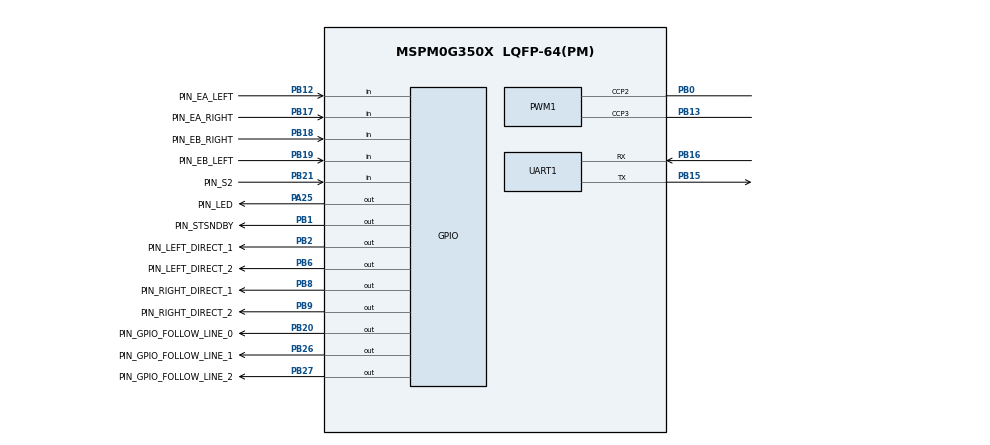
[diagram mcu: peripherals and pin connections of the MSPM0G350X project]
/**
 * @cliArgs --device "MSPM0G350X" --part "Default" --package "LQFP-64(PM)" --product "mspm0_sdk@2.04.00.06"
 * @versions {"tool":"1.24.0+4110"}
 */

/**
 * Import the modules used in this configuration.
 */
const ADC12  = scripting.addModule("/ti/driverlib/ADC12", {}, false);
const ADC121 = ADC12.addInstance();
const GPIO   = scripting.addModule("/ti/driverlib/GPIO", {}, false);
const GPIO1  = GPIO.addInstance();
const GPIO2  = GPIO.addInstance();
const GPIO3  = GPIO.addInstance();
const GPIO4  = GPIO.addInstance();
const GPIO5  = GPIO.addInstance();
const GPIO6  = GPIO.addInstance();
const PWM    = scripting.addModule("/ti/driverlib/PWM", {}, false);
const PWM1   = PWM.addInstance();
const SYSCTL = scripting.addModule("/ti/driverlib/SYSCTL");
const TIMER  = scripting.addModule("/ti/driverlib/TIMER", {}, false);
const TIMER1 = TIMER.addInstance();
const TIMER2 = TIMER.addInstance();
const UART   = scripting.addModule("/ti/driverlib/UART", {}, false);
const UART1  = UART.addInstance();

/**
 * Write custom configuration values to the imported modules.
 */
const divider6       = system.clockTree["PLL_CLK2X_DIV"];
divider6.divideValue = 4;

const divider7       = system.clockTree["PLL_PDIV"];
divider7.divideValue = 2;

const divider9       = system.clockTree["UDIV"];
divider9.divideValue = 2;

const multiplier2         = system.clockTree["PLL_QDIV"];
multiplier2.multiplyValue = 10;

const mux8       = system.clockTree["HSCLKMUX"];
mux8.inputSelect = "HSCLKMUX_SYSPLL2X";

ADC121.$name                             = "ADC12_FOLLOW_LINE";
ADC121.enableDMA                         = false;
ADC121.sampClkDiv                        = "DL_ADC12_CLOCK_DIVIDE_8";
ADC121.adcMem0_name                      = "ADC_Channel0";
ADC121.powerDownMode                     = "DL_ADC12_POWER_DOWN_MODE_MANUAL";
ADC121.sampleTime0                       = "0";
ADC121.peripheral.$assign                = "ADC0";
ADC121.peripheral.adcPin0.$assign        = "PA27";
ADC121.adcPin0Config.hideOutputInversion = scripting.forceWrite(false);
ADC121.adcPin0Config.$name               = "ti_driverlib_gpio_GPIOPinGeneric12";

const Board = scripting.addModule("/ti/driverlib/Board", {}, false);

GPIO1.$name                              = "GPIO_MOTOR";
GPIO1.port                               = "PORTB";
GPIO1.associatedPins.create(5);
GPIO1.associatedPins[0].$name            = "PIN_STSNDBY";
GPIO1.associatedPins[0].pin.$assign      = "PB1";
GPIO1.associatedPins[1].$name            = "PIN_LEFT_DIRECT_1";
GPIO1.associatedPins[1].internalResistor = "PULL_DOWN";
GPIO1.associatedPins[1].pin.$assign      = "PB2";
GPIO1.associatedPins[2].$name            = "PIN_LEFT_DIRECT_2";
GPIO1.associatedPins[2].internalResistor = "PULL_DOWN";
GPIO1.associatedPins[2].pin.$assign      = "PB6";
GPIO1.associatedPins[3].$name            = "PIN_RIGHT_DIRECT_1";
GPIO1.associatedPins[3].internalResistor = "PULL_DOWN";
GPIO1.associatedPins[3].pin.$assign      = "PB8";
GPIO1.associatedPins[4].$name            = "PIN_RIGHT_DIRECT_2";
GPIO1.associatedPins[4].internalResistor = "PULL_DOWN";
GPIO1.associatedPins[4].pin.$assign      = "PB9";

GPIO2.$name                              = "GPIO_ENCODER_LEFT";
GPIO2.associatedPins.create(2);
GPIO2.associatedPins[0].$name            = "PIN_EA_LEFT";
GPIO2.associatedPins[0].direction        = "INPUT";
GPIO2.associatedPins[0].assignedPort     = "PORTB";
GPIO2.associatedPins[0].interruptEn      = true;
GPIO2.associatedPins[0].polarity         = "FALL";
GPIO2.associatedPins[0].internalResistor = "PULL_UP";
GPIO2.associatedPins[0].pin.$assign      = "PB12";
GPIO2.associatedPins[1].$name            = "PIN_EB_LEFT";
GPIO2.associatedPins[1].direction        = "INPUT";
GPIO2.associatedPins[1].internalResistor = "PULL_UP";
GPIO2.associatedPins[1].assignedPort     = "PORTB";
GPIO2.associatedPins[1].pin.$assign      = "PB19";

GPIO3.$name                              = "GPIO_ENCODER_RIGHT";
GPIO3.associatedPins.create(2);
GPIO3.associatedPins[0].$name            = "PIN_EA_RIGHT";
GPIO3.associatedPins[0].direction        = "INPUT";
GPIO3.associatedPins[0].internalResistor = "PULL_UP";
GPIO3.associatedPins[0].interruptEn      = true;
GPIO3.associatedPins[0].polarity         = "FALL";
GPIO3.associatedPins[0].pin.$assign      = "PB17";
GPIO3.associatedPins[1].$name            = "PIN_EB_RIGHT";
GPIO3.associatedPins[1].direction        = "INPUT";
GPIO3.associatedPins[1].internalResistor = "PULL_UP";
GPIO3.associatedPins[1].pin.$assign      = "PB18";

GPIO4.$name                               = "GPIO_SWICH";
GPIO4.associatedPins[0].$name             = "PIN_S2";
GPIO4.associatedPins[0].direction         = "INPUT";
GPIO4.associatedPins[0].internalResistor  = "PULL_UP";
GPIO4.associatedPins[0].interruptEn       = true;
GPIO4.associatedPins[0].polarity          = "FALL";
GPIO4.associatedPins[0].launchPadShortcut = "Button3En";
GPIO4.associatedPins[0].pin.$assign       = "PB21";

GPIO5.$name                         = "GPIO_FOLLOW_LINE";
GPIO5.associatedPins.create(3);
GPIO5.associatedPins[0].$name       = "PIN_GPIO_FOLLOW_LINE_0";
GPIO5.associatedPins[0].pin.$assign = "PB20";
GPIO5.associatedPins[1].$name       = "PIN_GPIO_FOLLOW_LINE_1";
GPIO5.associatedPins[1].pin.$assign = "PB26";
GPIO5.associatedPins[2].$name       = "PIN_GPIO_FOLLOW_LINE_2";
GPIO5.associatedPins[2].pin.$assign = "PB27";

GPIO6.$name                         = "GPIO_LED";
GPIO6.associatedPins[0].$name       = "PIN_LED";
GPIO6.associatedPins[0].pin.$assign = "PA25";

PWM1.$name                      = "PWM_MOTOR";
PWM1.clockDivider               = 2;
PWM1.timerCount                 = 4000;
PWM1.timerStartTimer            = true;
PWM1.ccIndex                    = [2,3];
PWM1.peripheral.$assign         = "TIMA0";
PWM1.peripheral.ccp2Pin.$assign = "PB0";
PWM1.peripheral.ccp3Pin.$assign = "PB13";
PWM1.PWM_CHANNEL_2.$name        = "ti_driverlib_pwm_PWMTimerCC0";
PWM1.PWM_CHANNEL_3.$name        = "ti_driverlib_pwm_PWMTimerCC1";
PWM1.ccp2PinConfig.$name        = "ti_driverlib_gpio_GPIOPinGeneric4";
PWM1.ccp3PinConfig.$name        = "ti_driverlib_gpio_GPIOPinGeneric5";

SYSCTL.forceDefaultClkConfig = true;
SYSCTL.clockTreeEn           = true;

TIMER1.$name              = "TIMER_PID";
TIMER1.timerClkSrc        = "LFCLK";
TIMER1.timerClkDiv        = 8;
TIMER1.timerClkPrescale   = 41;
TIMER1.timerPeriod        = "500 ms";
TIMER1.interrupts         = ["ZERO"];
TIMER1.peripheral.$assign = "TIMA1";

TIMER2.$name              = "TIMER_GENERAL";
TIMER2.timerClkSrc        = "LFCLK";
TIMER2.timerClkPrescale   = 41;
TIMER2.timerClkDiv        = 8;
TIMER2.timerPeriod        = "20s";
TIMER2.interrupts         = ["ZERO"];
TIMER2.peripheral.$assign = "TIMG6";

UART1.$name                            = "UART_BLUEUART";
UART1.targetBaudRate                   = 115200;
UART1.peripheral.$assign               = "UART2";
UART1.peripheral.rxPin.$assign         = "PB16";
UART1.peripheral.txPin.$assign         = "PB15";
UART1.txPinConfig.direction            = scripting.forceWrite("OUTPUT");
UART1.txPinConfig.hideOutputInversion  = scripting.forceWrite(false);
UART1.txPinConfig.onlyInternalResistor = scripting.forceWrite(false);
UART1.txPinConfig.passedPeripheralType = scripting.forceWrite("Digital");
UART1.txPinConfig.$name                = "ti_driverlib_gpio_GPIOPinGeneric2";
UART1.rxPinConfig.hideOutputInversion  = scripting.forceWrite(false);
UART1.rxPinConfig.onlyInternalResistor = scripting.forceWrite(false);
UART1.rxPinConfig.passedPeripheralType = scripting.forceWrite("Digital");
UART1.rxPinConfig.$name                = "ti_driverlib_gpio_GPIOPinGeneric3";
UART1.rxPinConfig.enableConfig         = true;
UART1.rxPinConfig.internalResistor     = "PULL_UP";

/**
 * Pinmux solution for unlocked pins/peripherals. This ensures that minor changes to the automatic solver in a future
 * version of the tool will not impact the pinmux you originally saw.  These lines can be completely deleted in order to
 * re-solve from scratch.
 */
Board.peripheral.$suggestSolution          = "DEBUGSS";
Board.peripheral.swclkPin.$suggestSolution = "PA20";
Board.peripheral.swdioPin.$suggestSolution = "PA19";
